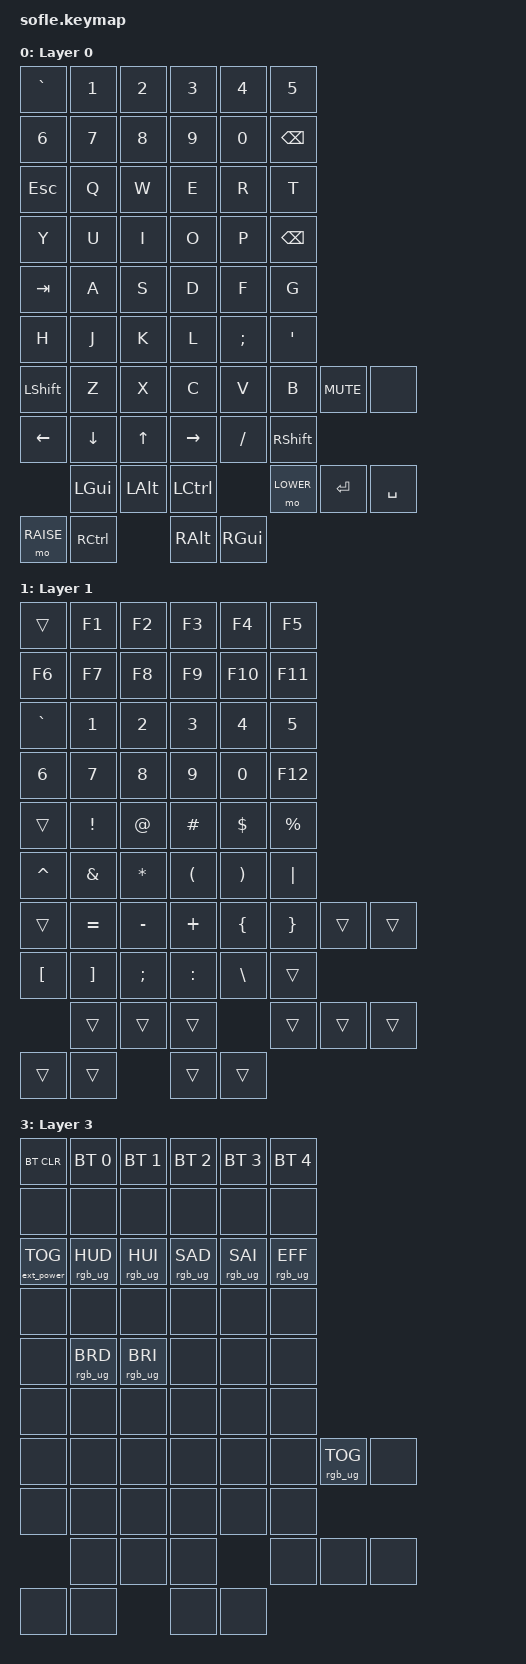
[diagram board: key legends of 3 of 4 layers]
/*
 * Copyright (c) 2020 The ZMK Contributors
 *
 * SPDX-License-Identifier: MIT
 */

#include <behaviors.dtsi>
#include <dt-bindings/zmk/keys.h>
#include <dt-bindings/zmk/bt.h>
#include <dt-bindings/zmk/rgb.h>
#include <dt-bindings/zmk/mouse.h>
#include <dt-bindings/zmk/ext_power.h>
#include <dt-bindings/zmk/outputs.h>
#include <input/processors.dtsi>

#define BASE 0
#define LOWER 1
#define RAISE 2
#define ADJUST 3

/ {
    behaviors {
        mmv {
            acceleration-exponent = <1>;
            time-to-max-speed-ms = <900>;
            delay-ms = <0>;
        };
        msc {
            acceleration-exponent = <1>;
            time-to-max-speed-ms = <400>;
            delay-ms = <0>;
        };
    };

    scroll_encoder: scroll_encoder {
        compatible = "zmk,behavior-sensor-rotate";
        #sensor-binding-cells = <0>;
        bindings = <&msc SCRL_DOWN>, <&msc SCRL_UP>;
        tap-ms = <30>;
    };

    conditional_layers {
        compatible = "zmk,conditional-layers";
        adjust_layer {
            if-layers = <LOWER RAISE>;
            then-layer = <ADJUST>;
        };
    };

    keymap {
        compatible = "zmk,keymap";

        default_layer {
            display-name = "Layer 0";
            bindings = <
                &kp GRAVE &kp N1 &kp N2   &kp N3   &kp N4    &kp N5
                &kp N6    &kp N7 &kp N8   &kp N9   &kp N0    &kp BSPC
                &kp ESC   &kp Q  &kp W    &kp E    &kp R     &kp T
                &kp Y     &kp U  &kp I    &kp O    &kp P     &kp BSPC
                &kp TAB   &kp A  &kp S    &kp D    &kp F     &kp G
                &kp H     &kp J  &kp K    &kp L    &kp SEMI  &kp SQT
                &kp LSHFT &kp Z  &kp X    &kp C    &kp V     &kp B      &kp C_MUTE &none
                &kp LEFT  &kp DOWN &kp UP &kp RIGHT &kp FSLH &kp RSHFT
                             &kp LGUI &kp LALT &kp LCTRL &mo LOWER  &kp RET    &kp SPACE
                 &mo RAISE  &kp RCTRL &kp RALT  &kp RGUI
            >;

            sensor-bindings = <&inc_dec_kp C_VOL_UP C_VOL_DN>;
        };

        lower_layer {
            display-name = "Layer 1";
            bindings = <
                &trans    &kp F1    &kp F2    &kp F3      &kp F4    &kp F5
                &kp F6    &kp F7   &kp F8    &kp F9    &kp F10   &kp F11
                &kp GRAVE &kp N1   &kp N2    &kp N3    &kp N4    &kp N5
                &kp N6    &kp N7   &kp N8    &kp N9    &kp N0    &kp F12
                &trans    &kp EXCL &kp AT    &kp HASH  &kp DLLR  &kp PRCNT
                &kp CARET &kp AMPS &kp ASTRK &kp LPAR  &kp RPAR  &kp PIPE
                &trans    &kp EQUAL &kp MINUS &kp PLUS &kp LBRC  &kp RBRC
                &trans &trans &kp LBKT  &kp RBKT &kp SEMI  &kp COLON &kp BSLH  &trans
                             &trans    &trans      &trans    &trans     &trans &trans
                  &trans    &trans   &trans    &trans
            >;
            sensor-bindings = <&scroll_encoder>;
        };

        raise_layer {
            display-name = "Layer 2";
            bindings = <
                &bt BT_CLR &bt BT_SEL 0 &bt BT_SEL 1 &bt BT_SEL 2 &bt BT_SEL 3 &bt BT_SEL 4
                &mmv MOVE_UP &trans &trans &trans &trans &trans
                &trans &kp INS &kp PSCRN &kp K_CMENU &trans &trans
                &kp PG_UP &mmv MOVE_DOWN &kp UP &trans &kp N0 &trans
                &trans &kp LALT &kp LCTRL &kp LSHFT &trans &kp CLCK
                &kp PG_DN &mmv MOVE_LEFT &kp LEFT &kp DOWN &kp RIGHT &kp DEL &kp BSPC
                &trans &kp K_UNDO &kp K_CUT &kp K_COPY &kp K_PASTE &trans &trans &trans &trans &trans &trans &trans &trans &trans
                &trans &trans &trans &trans &trans &trans &trans &trans &trans &trans
            >;
            sensor-bindings = <&scroll_encoder>;
        };

        adjust_layer {
            display-name = "Layer 3";
            bindings = <
                &bt BT_CLR        &bt BT_SEL 0    &bt BT_SEL 1    &bt BT_SEL 2    &bt BT_SEL 3    &bt BT_SEL 4
                &none &none &none &none &none &none
                &ext_power EP_TOG &rgb_ug RGB_HUD &rgb_ug RGB_HUI &rgb_ug RGB_SAD &rgb_ug RGB_SAI &rgb_ug RGB_EFF
                &none &none &none &none &none &none
                &none &rgb_ug RGB_BRD &rgb_ug RGB_BRI &none           &none           &none
                &none &none &none &none &none &none
                &none &none &none &none &none &none &rgb_ug RGB_TOG &none &none &none &none &none &none &none
                         &none           &none           &none           &none            &none           &none  &none &none &none &none
            >;
            sensor-bindings = <&scroll_encoder>;
        };
    };
};
